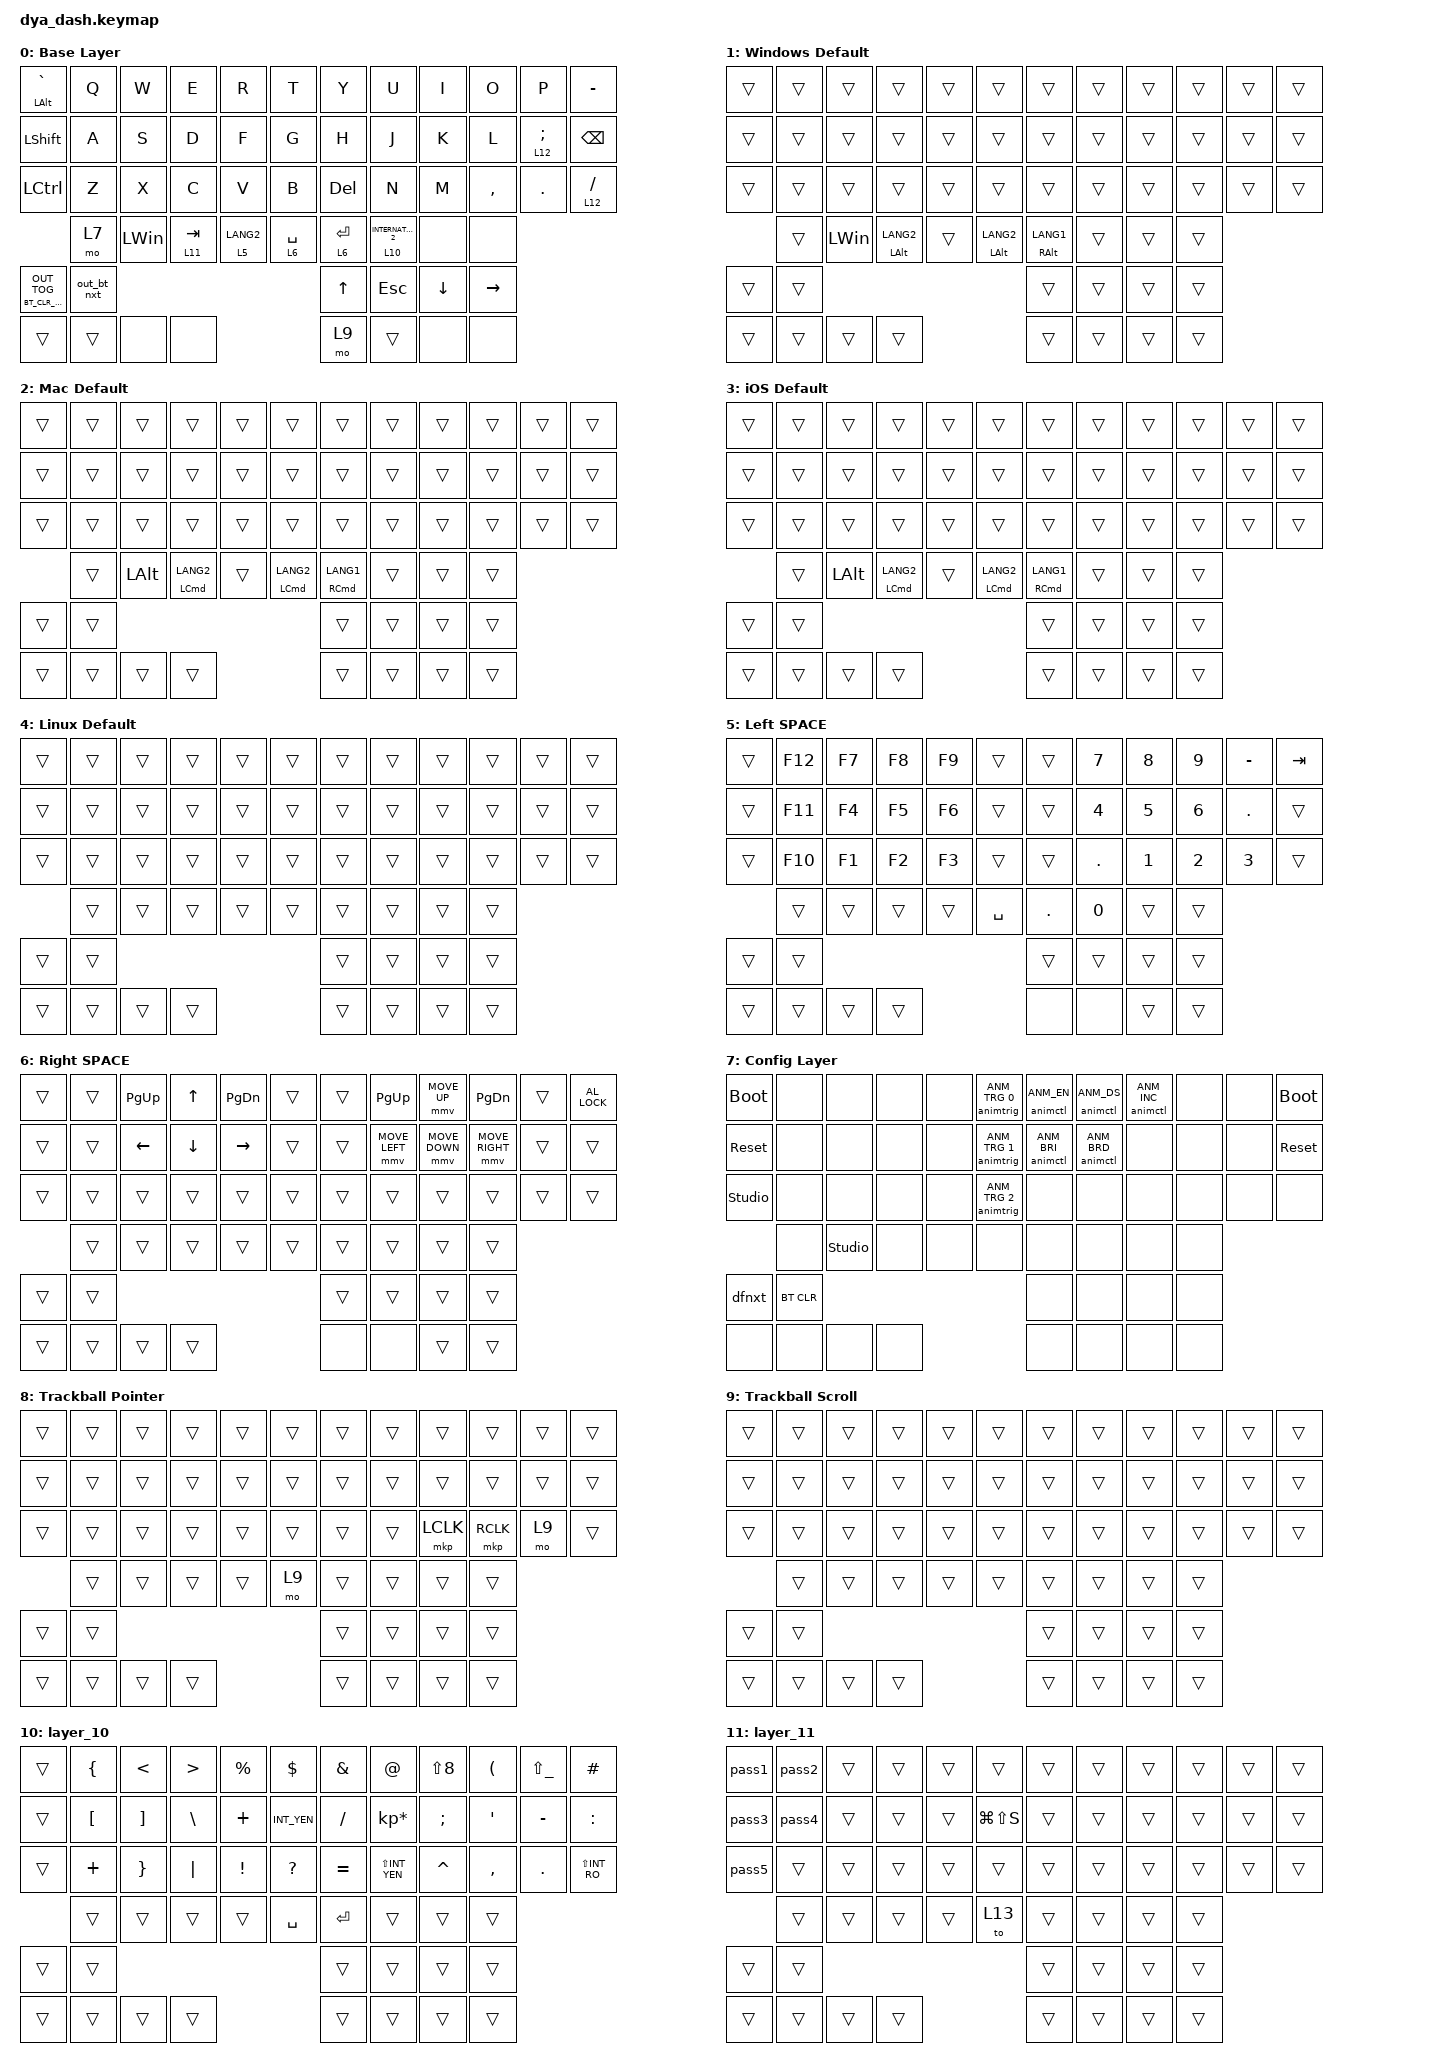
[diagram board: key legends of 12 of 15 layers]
#include <behaviors/mouse_move.dtsi>
#include <behaviors/animation_control.dtsi>
#include <behaviors/animation_trigger.dtsi>
#include <dt-bindings/zmk/mouse.h>
#include <dt-bindings/zmk_driver_animation/animation_control.h>
#include <dt-bindings/zmk_driver_animation/animation_trigger.h>
#include <dt-bindings/zmk_behavior_default_layer/default_layer.h>
#include <behaviors.dtsi>
#include <dt-bindings/zmk/bt.h>
#include <dt-bindings/zmk/keys.h>
#include <dt-bindings/zmk/outputs.h>
#include <dt-bindings/zmk/pointing.h>

// Layer definitions

#define DEFAULT_L 0
#define WINDOWS_L 1
#define MAC_L 2
#define IOS_L 3
#define LINUX_L 4
#define LEFT_L 5
#define RIGHT_L 6
#define CONFIG_L 7
#define TRACKBALL_L 8
#define SCROLL_L 9
#define EXT1_L 10
#define EXT2_L 11
#define EXT3_L 12

&trackball_listener {
    // When trackball is used, TRACKBALL_L layer is activated.
    // After 500ms of trackball inactivity, the layer is deactivated.

    input-processors = <&zip_temp_layer TRACKBALL_L 500>;
};

&trackball_scroller { layers = <SCROLL_L>; };

&trackball_listener_l { input-processors = <&zip_temp_layer TRACKBALL_L 500>; };

&trackball_scroller_l { layers = <SCROLL_L>; };

&zip_temp_layer { excluded-positions = <19 20 21 22 32 33 41 52 53 54 55 56 57 58 59>; };

/ {
    behaviors {
        // ctrl+h as backspace

        hbackspace: h_or_ctrl_backspace {
            compatible = "zmk,behavior-mod-morph";
            #binding-cells = <0>;
            bindings = <&kp H>, <&kp BACKSPACE>;

            mods = <(MOD_LCTL)>;
        };

        // ctrl+j as enter

        jenter: j_or_ctrl_enter {
            compatible = "zmk,behavior-mod-morph";
            #binding-cells = <0>;
            bindings = <&kp J>, <&kp ENTER>;

            mods = <(MOD_LCTL)>;
        };

        // output for tap, bt for hold

        outbt: out_bt {
            compatible = "zmk,behavior-hold-tap";
            #binding-cells = <2>;
            flavor = "tap-preferred";
            tapping-term-ms = <1000>;
            bindings = <&bt1param>, <&out>;

            display-name = "Out-BT";
        };

        tog_off: toggle_layer_off_only {
            compatible = "zmk,behavior-toggle-layer";
            #binding-cells = <1>;
            display-name = "Toggle Layer Off";
            toggle-mode = "off";
        };
    };

    macros {
        out_bt_nxt: out_bt_nxt {
            compatible = "zmk,behavior-macro";
            #binding-cells = <0>;
            wait-ms = <50>;

            // Disconnect from all once for reliable connection to selected profile.
            // ZMK automatically reconnects to current profile right after disconnection.

            bindings = <&out OUT_BLE &bt BT_NXT &bt BT_DISC 0 &bt BT_DISC 1 &bt BT_DISC 2 &bt BT_DISC 3 &bt BT_DISC 4>;
        };

        dfnxt: dfnxt {
            compatible = "zmk,behavior-macro";
            #binding-cells = <0>;
            bindings = <&df DF_INC &animtrig ANM_TRG 2>;
        };

        // macro to use &bt in hold-tap. two param command is not supported in hold-tap for now.

        bt1param: bt_1param {
            compatible = "zmk,behavior-macro-one-param";
            #binding-cells = <1>;
            wait-ms = <0>;
            bindings = <&macro_param_1to1 &bt MACRO_PLACEHOLDER 0>;
        };

        // diactivate speficied layer and execute &mo to disable trackball temp layer disable callback

        mo2: mo2 {
            compatible = "zmk,behavior-macro-one-param";
            #binding-cells = <1>;
            bindings = <&macro_param_1to1 &tog_off MACRO_PLACEHOLDER &macro_param_1to1 &mo MACRO_PLACEHOLDER>;
        };

        pass1: pass1 {
            compatible = "zmk,behavior-macro";
            #binding-cells = <0>;
            bindings = <&kp NUMBER_0 &kp NUMBER_4 &kp NUMBER_2 &kp NUMBER_9 &kp NUMBER_0 &kp NUMBER_4 &kp NUMBER_2 &kp NUMBER_9>;
            label = "PASS1";
        };

        pass2: pass2 {
            compatible = "zmk,behavior-macro";
            #binding-cells = <0>;
            bindings = <&kp NUMBER_7 &kp NUMBER_1 &kp NUMBER_8 &kp NUMBER_8 &kp NUMBER_7 &kp NUMBER_1 &kp NUMBER_8 &kp NUMBER_8>;
            label = "PASS2";
        };

        pass3: pass3 {
            compatible = "zmk,behavior-macro";
            #binding-cells = <0>;
            bindings = <&kp W &kp S &kp W &kp S &kp W &kp S>;
            label = "PASS3";
        };

        pass4: pass4 {
            compatible = "zmk,behavior-macro";
            #binding-cells = <0>;
            bindings = <&kp W &kp S &kp H &kp Z &kp J &kp W &kp P &kp NUMBER_0 &kp S &kp NUMBER_2>;
            label = "PASS4";
        };

        pass5: pass5 {
            compatible = "zmk,behavior-macro";
            #binding-cells = <0>;
            bindings = <&kp Q &kp U &kp B &kp E &kp L &kp E &kp Y &kp Q &kp U &kp B &kp E &kp L &kp E &kp Y>;
            label = "PASS5";
        };
    };

    combos {
        compatible = "zmk,combos";

        // Right side's setting button shares input pin with arrow keys.
        // It works as a combo of two arrow keys.

        setting_r1 {
            timeout-ms = <10>;
            key-positions = <47 50>;
            bindings = <&kp C_VOL_DN>;
        };

        setting_r2 {
            timeout-ms = <10>;
            key-positions = <47 49>;
            bindings = <&kp C_VOL_UP>;
        };
    };

    keymap {
        compatible = "zmk,keymap";

        // template {
        //     bindings = <
        //         &trans      &trans      &trans      &trans      &trans      &trans      /**/ &trans      &trans      &trans      &trans      &trans      &trans
        //         &trans      &trans      &trans      &trans      &trans      &trans      /**/ &trans      &trans      &trans      &trans      &trans      &trans
        //         &trans      &trans      &trans      &trans      &trans      &trans      /**/ &trans      &trans      &trans      &trans      &trans      &trans
        //                     &trans      &trans      &trans      &trans      &trans      /**/ &trans      &trans      &trans      &trans
        //
        //         &trans      &trans                                                      /**/ &trans      &trans      &trans      &trans
        //         &trans      &trans      &trans      &trans                              /**/ &trans      &trans      &trans      &trans
        //     >;
        // };

        default_layer {
            display-name = "Base Layer";

            // --------------------------------------------------------------------------------------------------------------------------------------------------
            // |   TAB   |    Q    |    W    |    E       |    R             |    T    |            |    Y    |    U             |    I     |    O    |    P    |    [    |
            // |   CTRL  |    A    |    S    |    D       |    F             |    G    |            |    H    |    J             |    K     |    L    |    ;    |    '    |
            // |  SHIFT  |    Z    |    X    |    C       |    V             |    B    |            |    B    |    N             |    M     |    ,    |    .    |    /    |
            //           |   ALT   |   CMD   |   Cmd (En) |  SPACE or LOWER  |Cmd (En) |            | Cmd(ja) |  Space or LOWER2 |          |         |
            // --------------------------------------------------------------------------------------------------------------------------------------------------
            // | BLE     |  USB    |                                                                |  left   | up   | down | right |
            // | touch1  | touch2  | touch3  | touch 4    |                                         | touch1  | touch2  | touch3  | touch 4 |

            bindings = <
&mt LEFT_ALT GRAVE         &kp Q        &kp W     &kp E       &kp R        &kp T        &kp Y         &kp U                   &kp I     &kp O      &kp P             &kp MINUS
&kp LEFT_SHIFT             &kp A        &kp S     &kp D       &kp F        &kp G        &kp H         &kp J                   &kp K     &kp L      &lt 12 SEMICOLON  &kp BACKSPACE
&kp LCTRL                  &kp Z        &kp X     &kp C       &kp V        &kp B        &kp DELETE    &kp N                   &kp M     &kp COMMA  &kp DOT           &lt 12 SLASH
                           &mo 7        &kp LWIN  &lt 11 TAB  &lt 5 LANG2  &lt 6 SPACE  &lt 6 RETURN  &lt 10 INTERNATIONAL_2  &none     &none
&outbt BT_CLR_CMD OUT_TOG  &out_bt_nxt                                                  &kp UP        &kp ESC                 &kp DOWN  &kp RIGHT
&trans                     &trans       &none     &none                                 &mo 9         &trans                  &none     &none
            >;
        };

        windows_default_layer {
            display-name = "Windows Default";
            bindings = <
&trans  &trans  &trans    &trans          &trans  &trans          &trans          &trans  &trans  &trans  &trans  &trans
&trans  &trans  &trans    &trans          &trans  &trans          &trans          &trans  &trans  &trans  &trans  &trans
&trans  &trans  &trans    &trans          &trans  &trans          &trans          &trans  &trans  &trans  &trans  &trans
        &trans  &kp LWIN  &mt LALT LANG2  &trans  &mt LALT LANG2  &mt RALT LANG1  &trans  &trans  &trans
&trans  &trans                                                    &trans          &trans  &trans  &trans
&trans  &trans  &trans    &trans                                  &trans          &trans  &trans  &trans
            >;
        };

        mac_default_layer {
            display-name = "Mac Default";
            bindings = <
&trans  &trans  &trans    &trans          &trans  &trans          &trans          &trans  &trans  &trans  &trans  &trans
&trans  &trans  &trans    &trans          &trans  &trans          &trans          &trans  &trans  &trans  &trans  &trans
&trans  &trans  &trans    &trans          &trans  &trans          &trans          &trans  &trans  &trans  &trans  &trans
        &trans  &kp LALT  &mt LCMD LANG2  &trans  &mt LCMD LANG2  &mt RCMD LANG1  &trans  &trans  &trans
&trans  &trans                                                    &trans          &trans  &trans  &trans
&trans  &trans  &trans    &trans                                  &trans          &trans  &trans  &trans
            >;
        };

        ios_default_layer {
            display-name = "iOS Default";
            bindings = <
&trans  &trans  &trans    &trans          &trans  &trans          &trans          &trans  &trans  &trans  &trans  &trans
&trans  &trans  &trans    &trans          &trans  &trans          &trans          &trans  &trans  &trans  &trans  &trans
&trans  &trans  &trans    &trans          &trans  &trans          &trans          &trans  &trans  &trans  &trans  &trans
        &trans  &kp LALT  &mt LCMD LANG2  &trans  &mt LCMD LANG2  &mt RCMD LANG1  &trans  &trans  &trans
&trans  &trans                                                    &trans          &trans  &trans  &trans
&trans  &trans  &trans    &trans                                  &trans          &trans  &trans  &trans
            >;
        };

        linux_default_layer {
            display-name = "Linux Default";
            bindings = <
&trans  &trans  &trans  &trans  &trans  &trans  &trans  &trans  &trans  &trans  &trans  &trans
&trans  &trans  &trans  &trans  &trans  &trans  &trans  &trans  &trans  &trans  &trans  &trans
&trans  &trans  &trans  &trans  &trans  &trans  &trans  &trans  &trans  &trans  &trans  &trans
        &trans  &trans  &trans  &trans  &trans  &trans  &trans  &trans  &trans
&trans  &trans                                  &trans  &trans  &trans  &trans
&trans  &trans  &trans  &trans                  &trans  &trans  &trans  &trans
            >;
        };

        left_layer {
            display-name = "Left SPACE";

            // --------------------------------------------------------------------------------------------------------------------------------------------------------------------
            // |  ESC    |  !  |  @  |  #       |  $  |  %       |                           |  ^  |  &      |  *      |  (  |  )  |  ]  |
            // |         |  1  |  2  |  3       |  4  |  5       |                           |  6  |  7      |  8      |  9  |  0  |  \  |
            // |         |     |     |          |     |          |                           |  `  |  -      |  =      |  [  |  ]  |SHIFT|
            //           |     |     |          |     |          |                           |     |         |         |     |

            bindings = <
&trans  &kp F12  &kp F7  &kp F8  &kp F9  &trans     &trans   &kp NUMBER_7  &kp NUMBER_8  &kp NUMBER_9  &kp MINUS     &kp TAB
&trans  &kp F11  &kp F4  &kp F5  &kp F6  &trans     &trans   &kp NUMBER_4  &kp NUMBER_5  &kp NUMBER_6  &kp DOT       &trans
&trans  &kp F10  &kp F1  &kp F2  &kp F3  &trans     &trans   &kp DOT       &kp NUMBER_1  &kp NUMBER_2  &kp NUMBER_3  &trans
        &trans   &trans  &trans  &trans  &kp SPACE  &kp DOT  &kp NUMBER_0  &trans        &trans
&trans  &trans                                      &trans   &trans        &trans        &trans
&trans  &trans   &trans  &trans                     &none    &none         &trans        &trans
            >;
        };

        right_layer {
            display-name = "Right SPACE";
            bindings = <
&trans  &trans  &kp PG_UP  &kp UP    &kp PG_DN  &trans  &trans  &kp PG_UP       &mmv MOVE_UP    &kp PG_DN        &trans  &kp C_AL_LOCK
&trans  &trans  &kp LEFT   &kp DOWN  &kp RIGHT  &trans  &trans  &mmv MOVE_LEFT  &mmv MOVE_DOWN  &mmv MOVE_RIGHT  &trans  &trans
&trans  &trans  &trans     &trans    &trans     &trans  &trans  &trans          &trans          &trans           &trans  &trans
        &trans  &trans     &trans    &trans     &trans  &trans  &trans          &trans          &trans
&trans  &trans                                          &trans  &trans          &trans          &trans
&trans  &trans  &trans     &trans                       &none   &none           &trans          &trans
            >;
        };

        config_layer {
            display-name = "Config Layer";
            bindings = <
&bootloader     &none       &none           &none  &none  &animtrig ANM_TRG 0  &animctl ANM_EN   &animctl ANM_DS   &animctl ANM_INC  &none  &none  &bootloader
&sys_reset      &none       &none           &none  &none  &animtrig ANM_TRG 1  &animctl ANM_BRI  &animctl ANM_BRD  &none             &none  &none  &sys_reset
&studio_unlock  &none       &none           &none  &none  &animtrig ANM_TRG 2  &none             &none             &none             &none  &none  &none
                &none       &studio_unlock  &none  &none  &none                &none             &none             &none             &none
&dfnxt          &bt BT_CLR                                                     &none             &none             &none             &none
&none           &none       &none           &none                              &none             &none             &none             &none
            >;
        };

        trackball_layer {
            display-name = "Trackball Pointer";
            bindings = <
&trans  &trans  &trans  &trans  &trans  &trans  &trans  &trans  &trans     &trans     &trans  &trans
&trans  &trans  &trans  &trans  &trans  &trans  &trans  &trans  &trans     &trans     &trans  &trans
&trans  &trans  &trans  &trans  &trans  &trans  &trans  &trans  &mkp LCLK  &mkp RCLK  &mo 9   &trans
        &trans  &trans  &trans  &trans  &mo 9   &trans  &trans  &trans     &trans
&trans  &trans                                  &trans  &trans  &trans     &trans
&trans  &trans  &trans  &trans                  &trans  &trans  &trans     &trans
            >;
        };

        scroll_layer {
            display-name = "Trackball Scroll";
            bindings = <
&trans  &trans  &trans  &trans  &trans  &trans  &trans  &trans  &trans  &trans  &trans  &trans
&trans  &trans  &trans  &trans  &trans  &trans  &trans  &trans  &trans  &trans  &trans  &trans
&trans  &trans  &trans  &trans  &trans  &trans  &trans  &trans  &trans  &trans  &trans  &trans
        &trans  &trans  &trans  &trans  &trans  &trans  &trans  &trans  &trans
&trans  &trans                                  &trans  &trans  &trans  &trans
&trans  &trans  &trans  &trans                  &trans  &trans  &trans  &trans
            >;
        };

        layer_10 {
            bindings = <
&trans  &kp LBRC          &kp LESS_THAN      &kp GREATER_THAN  &kp PERCENT  &kp DOLLAR    &kp AMPERSAND  &kp AT_SIGN      &kp LS(N8)  &kp LPAR          &kp LS(UNDERSCORE)  &kp HASH
&trans  &kp LEFT_BRACKET  &kp RIGHT_BRACKET  &kp BSLH          &kp PLUS     &kp INT_YEN   &kp SLASH      &kp KP_ASTERISK  &kp SEMI    &kp SINGLE_QUOTE  &kp MINUS           &kp COLON
&trans  &kp PLUS          &kp RBRC           &kp PIPE          &kp EXCL     &kp QUESTION  &kp EQUAL      &kp LS(INT_YEN)  &kp CARET   &kp COMMA         &kp DOT             &kp LS(INT_RO)
        &trans            &trans             &trans            &trans       &kp SPACE     &kp ENTER      &trans           &trans      &trans
&trans  &trans                                                                            &trans         &trans           &trans      &trans
&trans  &trans            &trans             &trans                                       &trans         &trans           &trans      &trans
            >;
        };

        layer_11 {
            bindings = <
&pass1  &pass2  &trans  &trans  &trans  &trans         &trans  &trans  &trans  &trans  &trans  &trans
&pass3  &pass4  &trans  &trans  &trans  &kp LG(LS(S))  &trans  &trans  &trans  &trans  &trans  &trans
&pass5  &trans  &trans  &trans  &trans  &trans         &trans  &trans  &trans  &trans  &trans  &trans
        &trans  &trans  &trans  &trans  &to 13         &trans  &trans  &trans  &trans
&trans  &trans                                         &trans  &trans  &trans  &trans
&trans  &trans  &trans  &trans                         &trans  &trans  &trans  &trans
            >;
        };

        layer_12 {
            display-name = "TP_Sence";
            bindings = <
&kp TAB         &trans  &kp PG_UP  &kp UP        &kp PG_DN  &trans  &trans     &trans     &trans     &trans     &trans     &trans
&kp LEFT_SHIFT  &trans  &kp LEFT   &kp DOWN      &kp RIGHT  &trans  &mkp MCLK  &mkp LCLK  &mkp RCLK  &mo 9      &mkp MCLK  &mkp MCLK
&kp LCTRL       &trans  &trans     &trans        &trans     &trans  &trans     &mkp MCLK  &mkp LCLK  &mkp RCLK  &mo 9      &trans
                &trans  &trans     &kp LEFT_ALT  &trans     &mo 9   &mkp MB4   &mkp MB5   &trans     &trans
&trans          &trans                                              &trans     &trans     &trans     &trans
&trans          &trans  &trans     &trans                           &trans     &trans     &trans     &trans
            >;
        };

        layer_13 {
            display-name = "Layer 13";
            bindings = <
&kp TAB         &kp Q    &kp W   &kp E         &kp R   &kp T      &trans  &trans  &trans  &trans  &trans  &trans
&kp LEFT_SHIFT  &kp A    &kp S   &kp D         &kp F   &kp G      &trans  &trans  &trans  &trans  &trans  &trans
&kp LCTRL       &kp Z    &kp X   &kp C         &kp V   &kp B      &trans  &trans  &trans  &trans  &trans  &trans
                &kp ESC  &kp M   &kp LEFT_ALT  &mo 14  &kp SPACE  &trans  &trans  &trans  &trans
&trans          &trans                                            &trans  &to 0   &trans  &trans
&trans          &trans   &trans  &trans                           &trans  &trans  &trans  &trans
            >;
        };

        layer_14 {
            bindings = <
&trans  &kp F1        &kp F2        &kp F3        &kp F4        &kp F5        &trans  &trans  &trans  &trans  &trans  &trans
&trans  &kp NUMBER_1  &kp NUMBER_2  &kp NUMBER_3  &kp NUMBER_4  &kp NUMBER_5  &trans  &trans  &trans  &trans  &trans  &trans
&trans  &trans        &trans        &trans        &trans        &trans        &trans  &trans  &trans  &trans  &trans  &trans
        &trans        &trans        &trans        &trans        &trans        &trans  &trans  &trans  &trans
&trans  &trans                                                                &trans  &trans  &trans  &trans
&trans  &trans        &trans        &trans                                    &trans  &trans  &trans  &trans
            >;
        };
    };
};
